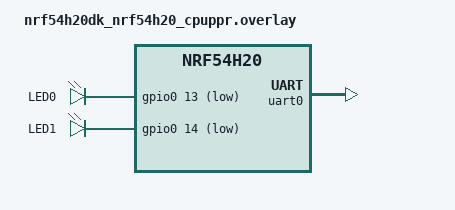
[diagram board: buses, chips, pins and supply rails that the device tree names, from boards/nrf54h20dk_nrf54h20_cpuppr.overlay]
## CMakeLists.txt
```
#
# Copyright (c) 2020 Nordic Semiconductor ASA
#
# SPDX-License-Identifier: LicenseRef-Nordic-5-Clause
#
cmake_minimum_required(VERSION 3.20.0)

find_package(Zephyr REQUIRED HINTS $ENV{ZEPHYR_BASE})

project(LED_strip_thread_network)

# NORDIC SDK APP START
target_sources(app PRIVATE src/main.c src/g_udp.c src/g_udp.h src/g_node.h)
# NORDIC SDK APP END

target_sources_ifdef(CONFIG_CLI_SAMPLE_MULTIPROTOCOL app PRIVATE src/ble.c)
target_sources_ifdef(CONFIG_CLI_SAMPLE_LOW_POWER app PRIVATE src/low_power.c)

if(CONFIG_CLI_SAMPLE_MULTIPROTOCOL AND CONFIG_OPENTHREAD_BLE_TCAT)
  message(FATAL_ERROR "Multiprotocol support and TCAT functionality are not compatible." )
endif()
```

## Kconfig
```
#
# Copyright (c) 2020 Nordic Semiconductor ASA
#
# SPDX-License-Identifier: LicenseRef-Nordic-5-Clause
#

menu "Zephyr Kernel"
source "Kconfig.zephyr"
endmenu

module = OT_COMMAND_LINE_INTERFACE
module-str = ot_cli
source "$(ZEPHYR_BASE)/subsys/logging/Kconfig.template.log_config"

config CLI_SAMPLE_LOW_POWER
	bool "Low power mode for the CLI sample"

config CLI_SAMPLE_MULTIPROTOCOL
	bool "Multiprotocol for the CLI sample"

config NRFX_GPIOTE0
	default y if SOC_SERIES_NRF51X || \
		     SOC_SERIES_NRF52X || \
		     (SOC_SERIES_NRF53X && !TRUSTED_EXECUTION_NONSECURE) || \
		     (SOC_SERIES_NRF91X && !TRUSTED_EXECUTION_NONSECURE)

config NRFX_GPIOTE1
	default y if (SOC_SERIES_NRF53X && TRUSTED_EXECUTION_NONSECURE) || \
		     (SOC_SERIES_NRF91X && TRUSTED_EXECUTION_NONSECURE)
```

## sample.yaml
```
sample:
  name: OpenThread CLI sample
  description: Test OpenThread Command Line Interface.

tests:
  sample.openthread.cli:
    sysbuild: true
    build_only: true
    tags:
      - ci_build
      - sysbuild
      - ci_samples_openthread
      - board
    platform_allow:
      - nrf52840dk/nrf52840
      - nrf52840dongle/nrf52840
    integration_platforms:
      - nrf52840dk/nrf52840
      - nrf52840dongle/nrf52840
  sample.openthread.cli.multiprotocol:
    sysbuild: true
    build_only: true
    tags:
      - ci_build
      - sysbuild
      - ci_samples_openthread
    platform_allow:
      - nrf52840dk/nrf52840
      - nrf52840dongle/nrf52840
    extra_args:
      - cli_SNIPPET="ci;logging;multiprotocol;tcp"
      - FILE_SUFFIX=ble
    integration_platforms:
      - nrf52840dk/nrf52840
      - nrf52840dongle/nrf52840
  sample.openthread.cli.singleprotocol:
    sysbuild: true
    build_only: true
    tags:
      - ci_build
      - sysbuild
      - ci_samples_openthread
    platform_allow:
      - nrf52840dk/nrf52840
      - nrf21540dk/nrf52840
      - nrf5340dk/nrf5340/cpuapp
      - nrf54l15dk/nrf54l15/cpuapp
      - nrf54l15dk/nrf54l10/cpuapp
      - nrf54l15dk/nrf54l15/cpuapp/ns
    extra_args: >
      cli_SNIPPET="ci;logging;tcp"
    integration_platforms:
      - nrf52840dk/nrf52840
      - nrf21540dk/nrf52840
      - nrf5340dk/nrf5340/cpuapp
      - nrf54l15dk/nrf54l15/cpuapp
      - nrf54l15dk/nrf54l10/cpuapp
      - nrf54l15dk/nrf54l15/cpuapp/ns
  sample.openthread.cli.usb:
    sysbuild: true
    build_only: true
    tags:
      - ci_build
      - sysbuild
      - ci_samples_openthread
    platform_allow:
      - nrf52840dk/nrf52840
      - nrf21540dk/nrf52840
      - nrf5340dk/nrf5340/cpuapp
    extra_args:
      - cli_SNIPPET="ci;logging;multiprotocol;tcp;usb"
      - FILE_SUFFIX=ble
    integration_platforms:
      - nrf52840dk/nrf52840
      - nrf21540dk/nrf52840
      - nrf5340dk/nrf5340/cpuapp
  sample.openthread.cli.low_power:
    sysbuild: true
    build_only: true
    tags:
      - ci_build
      - sysbuild
      - ci_samples_openthread
    platform_allow:
      - nrf52840dk/nrf52840
      - nrf5340dk/nrf5340/cpuapp
      - nrf54l15dk/nrf54l15/cpuapp
      - nrf54lm20dk/nrf54lm20a/cpuapp
    extra_args: >
      cli_SNIPPET="ci;low_power"
    integration_platforms:
      - nrf52840dk/nrf52840
      - nrf5340dk/nrf5340/cpuapp
      - nrf54l15dk/nrf54l15/cpuapp
      - nrf54lm20dk/nrf54lm20a/cpuapp
  # Build integration regression protection.
  sample.nrf_security.openthread.integration:
    sysbuild: true
    build_only: true
    tags:
      - sysbuild
      - ci_samples_openthread
    platform_allow: >
      nrf52840dk/nrf52840
    extra_args:
      - cli_SNIPPET=ci
      - CONFIG_NRF_SECURITY=y
    integration_platforms:
      - nrf52840dk/nrf52840
  sample.openthread.cli.tcat:
    sysbuild: true
    build_only: true
    tags:
      - ci_build
      - sysbuild
      - ci_samples_openthread
    platform_allow:
      - nrf52840dk/nrf52840
      - nrf21540dk/nrf52840
      - nrf5340dk/nrf5340/cpuapp
      - nrf54l15dk/nrf54l15/cpuapp
      - nrf54l15dk/nrf54l10/cpuapp
      - nrf54l15dk/nrf54l15/cpuapp/ns
    extra_args:
      - cli_SNIPPET="ci;tcat;tcp"
      - FILE_SUFFIX=ble
    integration_platforms:
      - nrf52840dk/nrf52840
      - nrf21540dk/nrf52840
      - nrf5340dk/nrf5340/cpuapp
      - nrf54l15dk/nrf54l15/cpuapp
      - nrf54l15dk/nrf54l10/cpuapp
      - nrf54l15dk/nrf54l15/cpuapp/ns
  sample.openthread.cli.diag_gpio:
    sysbuild: true
    build_only: true
    tags:
      - ci_build
      - sysbuild
      - ci_samples_openthread
    platform_allow:
      - nrf52840dk/nrf52840
      - nrf5340dk/nrf5340/cpuapp
      - nrf54l15dk/nrf54l15/cpuapp
      - nrf54l15dk/nrf54l10/cpuapp
      - nrf54l15dk/nrf54l15/cpuapp/ns
    extra_args: >
      cli_SNIPPET=diag_gpio
    integration_platforms:
      - nrf52840dk/nrf52840
      - nrf5340dk/nrf5340/cpuapp
      - nrf54l15dk/nrf54l15/cpuapp
      - nrf54l15dk/nrf54l10/cpuapp
      - nrf54l15dk/nrf54l15/cpuapp/ns
  sample.openthread.cli.l2:
    sysbuild: true
    build_only: true
    tags:
      - ci_build
      - sysbuild
      - ci_samples_openthread
    platform_allow:
      - nrf52840dk/nrf52840
      - nrf5340dk/nrf5340/cpuapp
      - nrf54l15dk/nrf54l15/cpuapp
      - nrf54l15dk/nrf54l10/cpuapp
      - nrf54lm20dk/nrf54lm20a/cpuapp
      - nrf54l15dk/nrf54l15/cpuapp/ns
    extra_args:
      - cli_SNIPPET="ci;l2;ci_l2"
    integration_platforms:
      - nrf52840dk/nrf52840
      - nrf5340dk/nrf5340/cpuapp
      - nrf54l15dk/nrf54l15/cpuapp
      - nrf54l15dk/nrf54l10/cpuapp
      - nrf54lm20dk/nrf54lm20a/cpuapp
      - nrf54l15dk/nrf54l15/cpuapp/ns
  sample.openthread.cli.multiprotocol.l2:
    sysbuild: true
    build_only: true
    tags:
      - ci_build
      - sysbuild
      - ci_samples_openthread
    platform_allow:
      - nrf52840dk/nrf52840
      - nrf5340dk/nrf5340/cpuapp
      - nrf54l15dk/nrf54l15/cpuapp
      - nrf54l15dk/nrf54l10/cpuapp
      - nrf54lm20dk/nrf54lm20a/cpuapp
      - nrf54l15dk/nrf54l15/cpuapp/ns
    extra_args:
      - cli_SNIPPET="ci;logging;multiprotocol;tcp;l2;ci_l2;logging_l2"
      - FILE_SUFFIX=ble
    integration_platforms:
      - nrf52840dk/nrf52840
      - nrf5340dk/nrf5340/cpuapp
      - nrf54l15dk/nrf54l15/cpuapp
      - nrf54l15dk/nrf54l10/cpuapp
      - nrf54lm20dk/nrf54lm20a/cpuapp
      - nrf54l15dk/nrf54l15/cpuapp/ns
```

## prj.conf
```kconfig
#
# Copyright (c) 2020 Nordic Semiconductor
#
# SPDX-License-Identifier: LicenseRef-Nordic-5-Clause
#

# Enable OpenThread
CONFIG_NETWORKING=y
CONFIG_OPENTHREAD=y
CONFIG_NET_L2_OPENTHREAD=y

# PANID in decimal format (0x0A8F)
CONFIG_OPENTHREAD_PANID=2703 
CONFIG_OPENTHREAD_XPANID="0A:8F:11:11:22:22:22:22"
CONFIG_OPENTHREAD_NETWORKKEY="0A:8F:22:33:44:55:66:77:88:99:aa:bb:cc:dd:0A:8F"
CONFIG_OPENTHREAD_CHANNEL=21
CONFIG_OPENTHREAD_NETWORK_NAME="Gabriel"
CONFIG_OPENTHREAD_FTD=y

CONFIG_NET_UDP=y
CONFIG_NET_IPV6=y
CONFIG_NET_IPV6_NBR_CACHE=y

# Network shell
CONFIG_SHELL=y
CONFIG_OPENTHREAD_SHELL=y
CONFIG_SHELL_ARGC_MAX=26
CONFIG_SHELL_CMD_BUFF_SIZE=416

# Increase Settings storage size
CONFIG_PM_PARTITION_SIZE_SETTINGS_STORAGE=0x8000

# Enable OpenThread features set
CONFIG_OPENTHREAD_NORDIC_LIBRARY_MASTER=y

CONFIG_GPIO=y
CONFIG_GPIO_SHELL=y
CONFIG_GPIO_NRFX=y
CONFIG_DK_LIBRARY=y
CONFIG_NRFX_GPPI=y



CONFIG_LOG=y
CONFIG_LOG_DEFAULT_LEVEL=3

CONFIG_LOG_BACKEND_UART=y
CONFIG_UART_CONSOLE=y
CONFIG_CONSOLE=y
```

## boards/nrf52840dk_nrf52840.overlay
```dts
/* SPDX-License-Identifier: Apache-2.0 */

/ {
	aliases {
		led0 = &led0;
		led1 = &led1;
		disp1 = &disp1;
	};

	leds {
		compatible = "gpio-leds";
		led0: led_0 {
			gpios = <&gpio0 13 GPIO_ACTIVE_LOW>;
			label = "LED0";
		};
	};

	disp1: disp_1 {
		gpios = <&gpio0 27 GPIO_ACTIVE_HIGH>;
		status = "okay";
	};
};

&gpio0 {
    status = "okay";
};

&uart0 {
	status = "okay";
	hw-flow-control;
};
```

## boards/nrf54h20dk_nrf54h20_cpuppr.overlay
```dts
/* SPDX-License-Identifier: Apache-2.0 */

/ {
	aliases {
		led0 = &led0;
		led1 = &led1;
	};

	leds {
		compatible = "gpio-leds";
		led0: led_0 {
			gpios = <&gpio0 13 GPIO_ACTIVE_LOW>;
			label = "LED0";
		};

		led1: led_1 {
			gpios = <&gpio0 14 GPIO_ACTIVE_LOW>;
			label = "LED1";
		};
	};
};

&gpiote130 {
	status = "okay";
};

&gpio9 {
	status = "okay";
};

&uart0 {
	status = "okay";
	hw-flow-control;
};
```

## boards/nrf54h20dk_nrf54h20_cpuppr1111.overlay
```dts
/* SPDX-License-Identifier: Apache-2.0 */

/ {
	aliases {
		led0 = &led0;
		led1 = &led1;
		disp1 = &disp1;
	};

	leds {
		compatible = "gpio-leds";
		led0: led_0 {
			gpios = <&gpio0 13 GPIO_ACTIVE_LOW>;
			label = "LED0";
		};
	};

	disp1: disp_1 {
			gpios = <&gpio0 27 GPIO_ACTIVE_HIGH>;
			status = "okay";
	};
};

&gpiote130 {
	status = "okay";
};

&gpio0 {
    status = "okay";
};

&uart0 {
	status = "okay";
	hw-flow-control;
};
```

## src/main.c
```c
/*
 * Copyright (c) 2020 Nordic Semiconductor ASA
 *
 * SPDX-License-Identifier: LicenseRef-Nordic-5-Clause
 */

#include <zephyr/kernel.h>
#include <zephyr/net/openthread.h>
#include <zephyr/net/net_l2.h>
#include <zephyr/drivers/gpio.h>
#include <openthread/thread.h>
#include <zephyr/drivers/uart.h>
#include <zephyr/syscalls/device.h>
#include <nrfx_gpiote.h>
#include "g_udp.h"

#define G_SERVER 1

LOG_MODULE_REGISTER(main, CONFIG_OT_COMMAND_LINE_INTERFACE_LOG_LEVEL);

#define WELLCOME_TEXT \
	"\n\r"\
	"\n\r"\
	"OpenThread Command Line Interface is now running.\n\r" \
	"Use the 'ot' keyword to invoke OpenThread commands e.g. " \
	"'ot thread start.'\n\r" \
	"For the full commands list refer to the OpenThread CLI " \
	"documentation at:\n\r" \
	"https://github.com/openthread/openthread/blob/master/src/cli/README.md\n\r"

/* The devicetree node identifier for the "led0" alias. */
#define LED0_NODE DT_ALIAS(led0)
#define LED1_NODE DT_ALIAS(led1)

// LED 1
#define GPIO003_PIN NRF_GPIO_PIN_MAP(0, 3) // For PCA10056
#define GPIO004_PIN NRF_GPIO_PIN_MAP(0, 4) // For PCA10056
#define GPIO028_PIN NRF_GPIO_PIN_MAP(0, 27) // For PCA10056
#define GPIO110_PIN NRF_GPIO_PIN_MAP(1, 10) // For PCA10056
#define GPIO111_PIN NRF_GPIO_PIN_MAP(1, 11) // For PCA10056
#define GPIO112_PIN NRF_GPIO_PIN_MAP(1, 12) // For PCA10056
#define GPIO113_PIN NRF_GPIO_PIN_MAP(1, 13) // For PCA10056
#define GPIO114_PIN NRF_GPIO_PIN_MAP(1, 14) // For PCA10056

// LED 2 
#define GPIO101_PIN NRF_GPIO_PIN_MAP(1, 1) // For PCA10056
#define GPIO102_PIN NRF_GPIO_PIN_MAP(1, 2) // For PCA10056
#define GPIO103_PIN NRF_GPIO_PIN_MAP(1, 3) // For PCA10056
#define GPIO104_PIN NRF_GPIO_PIN_MAP(1, 4) // For PCA10056
#define GPIO105_PIN NRF_GPIO_PIN_MAP(1, 5)// For PCA10056
#define GPIO107_PIN NRF_GPIO_PIN_MAP(1, 7) // For PCA10056
#define GPIO108_PIN NRF_GPIO_PIN_MAP(1, 8) // For PCA10056
#define GPIO109_PIN NRF_GPIO_PIN_MAP(1, 9) // For PCA10056

#define MAX_GPIOS 8

static uint8_t hour = 23;
static uint8_t minute = 40;

const uint8_t MASK_0 = 1 << 7;
const uint8_t MASK_1 = 1 << 6;
const uint8_t MASK_2 = 1 << 5;
const uint8_t MASK_3 = 1 << 4;
const uint8_t MASK_4 = 1 << 3;
const uint8_t MASK_5 = 1 << 2;
const uint8_t MASK_6 = 1 << 1;
const uint8_t MASK_7 = 1 << 0;

static bool showHour = false;

typedef struct {
	uint8_t gpios[MAX_GPIOS];
    uint8_t numbers[10];
} sled_t ; 

static const struct gpio_dt_spec led = GPIO_DT_SPEC_GET(LED0_NODE, gpios);
static const struct gpio_dt_spec led1 = GPIO_DT_SPEC_GET(LED1_NODE, gpios);

void openthread_network_start()
{
	openthread_init();

	int net_res = openthread_run();

	ot = openthread_get_default_instance();

	if(net_res != OT_ERROR_NONE)
		LOG_ERR("Openthread starting error [%d]", net_res);
		return;
	
	LOG_INF("Openthread network %s started ", otThreadGetNetworkName(ot));
	return;
}

extern void blink_led(void *p0, void *p1, void *p2)
{
	gpio_pin_configure_dt(&led, GPIO_OUTPUT_INACTIVE);
	gpio_pin_configure_dt(&led1, GPIO_OUTPUT_INACTIVE);
	
	while(1)
	{
		int role = otThreadGetDeviceRole(ot);

		if(role == OT_DEVICE_ROLE_ROUTER)
		{
			gpio_pin_set_dt(&led, 1);
		}
		else if(role == OT_DEVICE_ROLE_CHILD)
		{
			gpio_pin_toggle_dt(&led);
		}
		else
		{
			gpio_pin_set_dt(&led, 0);
		}

		if(role == OT_DEVICE_ROLE_LEADER)
		{
			gpio_pin_toggle_dt(&led1);
		}

		k_sleep(K_MSEC(1000));
	}
}

/*extern void controlTime(void *p0, void *p1, void *p2)
{
	gpio_pin_configure_dt(&disp1_0_27, GPIO_OUTPUT_ACTIVE);
	
	while(1)
	{
		gpio_pin_toggle_dt(&disp1_0_27);
	}
}*/

void activate_gpios(uint8_t number, bool pointActive, sled_t* led)
{
    uint8_t gpios_pos = led->numbers[number];
	for(int index = 0 ; index < MAX_GPIOS ; index++)
		nrf_gpio_pin_clear(led->gpios[index]);
	
	if(pointActive)
		nrf_gpio_pin_set(led->gpios[4]);

    if (gpios_pos & MASK_0)
        nrf_gpio_pin_set(led->gpios[0]);
    if (gpios_pos & MASK_1)
        nrf_gpio_pin_set(led->gpios[1]);
    if (gpios_pos & MASK_2)
        nrf_gpio_pin_set(led->gpios[2]);
    if (gpios_pos & MASK_3)
        nrf_gpio_pin_set(led->gpios[3]);
    if (gpios_pos & MASK_4)
        nrf_gpio_pin_set(led->gpios[4]);
    if (gpios_pos & MASK_5)
        nrf_gpio_pin_set(led->gpios[5]);
    if (gpios_pos & MASK_6)
        nrf_gpio_pin_set(led->gpios[6]);
    if (gpios_pos & MASK_7)
        nrf_gpio_pin_set(led->gpios[7]);
}


// Find the first digit
int firstDigit(int n)
{
    // Remove last digit from number
    // till only one digit is left
    while (n >= 10) 
        n /= 10;
    
    // return the first digit
    return n;
}

// Find the last digit
int lastDigit(int n)
{
    // return the last digit
    return (n % 10);
}

void updateTime(void)
{
    while(true)
    {        
        if (minute == 59)
        {
            minute = 0;
            if (hour == 23)
                hour = 0;
            else
                hour++;
        }
        else
            minute++;
		
		k_sleep(K_MSEC(60000));  
    }
}

K_THREAD_DEFINE(blink_led_tid, 1024, blink_led, NULL, NULL, NULL, K_LOWEST_APPLICATION_THREAD_PRIO, 0,0);
K_THREAD_DEFINE(update_ime_tid, 1024, updateTime, NULL, NULL, NULL, K_LOWEST_APPLICATION_THREAD_PRIO, 0,0);
//K_THREAD_DEFINE(controlTime_tid, 1024, controlTime, NULL, NULL, NULL, K_LOWEST_APPLICATION_THREAD_PRIO, 0,0);

int main(void)
{
	LOG_INF(WELLCOME_TEXT);

	LOG_INF("%d", GPIO028_PIN);
	LOG_INF("%d", GPIO101_PIN);
	LOG_INF("%d", GPIO110_PIN);
	LOG_INF("%d", GPIO111_PIN);


    sled_t sLed1 = {
        // GPIO003_PIN, GPIO004_PIN, GPIO028_PIN, GPIO110_PIN, GPIO111_PIN, GPIO112_PIN, GPIO113_PIN, GPIO114_PIN
		.gpios = {GPIO003_PIN, GPIO004_PIN, GPIO028_PIN, GPIO110_PIN, GPIO111_PIN, GPIO112_PIN, GPIO113_PIN, GPIO114_PIN},
        .numbers = {
           231, // 0
           36, // 1
           115, // 2
           118, // 3
           180, // 4
           214, // 5
           215, // 6
           100, // 7
           247, // 8
           244 // 9
        }
    };

	sled_t sLed2 = {
        // GPIO101_PIN, GPIO102_PIN, GPIO103_PIN, GPIO104_PIN, GPIO105_PIN, GPIO107_PIN, GPIO108_PIN, GPIO109_PIN
        .gpios = {GPIO103_PIN, GPIO102_PIN, GPIO101_PIN, GPIO104_PIN, GPIO105_PIN, GPIO107_PIN, GPIO108_PIN, GPIO109_PIN},
        .numbers = {
           231, // 0
           36, // 1
           115, // 2
           118, // 3
           180, // 4
           214, // 5
           215, // 6
           100, // 7
           247, // 8
           244 // 9
        }
    };

	openthread_network_start();

	if (!gpio_is_ready_dt(&led) || !gpio_is_ready_dt(&led1) ) {
		printf("GPIO not ready");
		return 0;
	}
	
//	k_thread_start(blink_led);
//	k_thread_start(controlTime);
	k_thread_start(updateTime);

	// LED 1
	for (uint8_t index = 0; index < MAX_GPIOS; index++)
	{
		nrf_gpio_cfg_output(sLed1.gpios[index]);
		nrf_gpio_cfg_output(sLed2.gpios[index]);
	}

	while (1)
	{

		showHour = !showHour;
		uint8_t digit1, digit2 = 0U;

		if(showHour)
		{
			digit1 = (uint8_t) firstDigit(hour);
			digit2 = (uint8_t) lastDigit(hour);
		}
		else
		{
			digit1 = (uint8_t) firstDigit(minute);
			digit2 = (uint8_t) lastDigit(minute);
		}

		activate_gpios(digit1, showHour, &sLed1);
		activate_gpios(digit2, showHour, &sLed2);

		k_sleep(K_MSEC(5000));
		//nrf_gpio_pin_set(sLed2.gpios[number]);                                                                                                                                       
    }
                                      

#if G_SERVER
	otError error = g_udp_start_server();
	if (error != OT_ERROR_NONE) {
        LOG_ERR("g_udp_start_server error: %d", error);
        return;
    }
#endif

	return 0;
}
```

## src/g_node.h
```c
#ifndef G_NODE
#define G_NODE

#include <openthread/thread.h>
#include <zephyr/net/openthread.h>

typedef struct g_node
{  
    uint8_t id;
    otIp6Address address;

} g_node_t;

#endif
```

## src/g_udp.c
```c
#include "g_udp.h"
#include "g_node.h"
#include <openthread/thread.h>
#include <zephyr/net/openthread.h>

LOG_MODULE_REGISTER(g_udp, CONFIG_OT_COMMAND_LINE_INTERFACE_LOG_LEVEL);

typedef struct node {
    g_node_t value;
    struct node *next;
    uint8_t size;
} node_t;

node_t* nodes = NULL;

node_t* addNode(node_t *head, g_node_t node)
{
    node_t *n = malloc(sizeof *n);
    if (!n) return head;
    n->value = node;
    n->next = head;
    return n;
}

void freeNodes(node_t *head) {
    while (head) {
        node_t *next = head->next;
        free(head);
        head = next;
    }
}

void printAddress(const otIp6Address*const addr)
{
	LOG_INF("%02x%02x:%02x%02x:%02x%02x:%02x%02x:%02x%02x:%02x%02x:%02x%02x:%02x%02x", 
            addr->mFields.m8[0],
            addr->mFields.m8[1],
            addr->mFields.m8[2],
            addr->mFields.m8[3],
            addr->mFields.m8[4],
            addr->mFields.m8[5],
            addr->mFields.m8[6],
            addr->mFields.m8[7],
            addr->mFields.m8[8],
            addr->mFields.m8[9],
            addr->mFields.m8[10],
            addr->mFields.m8[11],
            addr->mFields.m8[12],
            addr->mFields.m8[13],
            addr->mFields.m8[14],
            addr->mFields.m8[15]);
}

/* Callback when a message is received in the socket */
void g_control_handler(void *context,
                           otMessage *message,
                           const otMessageInfo *message_info)
{
    uint16_t length = otMessageGetLength(message);
    char buffer[length];
    memset(buffer, 0, sizeof(buffer));
    otMessageRead(message, 0, &buffer, length);
    
    if(buffer[0] == 0)
    {   
        uint8_t nodeId = atoi(buffer[1]);
        otIp6Address addr = message_info->mPeerAddr;
        g_node_t node = {1, addr};
        nodes = addNode(nodes, node);
    }


    return;
}

/* Callback when a message is received in the socket */
void g_node_handler(void *context,
                           otMessage *message,
                           const otMessageInfo *message_info)
{
    otIp6Address addr = message_info->mPeerAddr;
    printAddress(&message_info->mPeerAddr);
    g_node_t node = {1, addr};
    nodes = addNode(nodes, node);

    printAddress(&nodes->value.address);
    uint16_t length = otMessageGetLength(message);
    char buffer[length+1];
    memset(buffer, 0, sizeof(buffer));
    otMessageRead(message, 0, &buffer, length);
    buffer[length+1] = '\0'; 

    LOG_INF("Message type: %c", buffer[0]);

    if(buffer[0] == '0')
    {   
        int nodeId = atoi(&buffer[1]);
        otIp6Address addr = message_info->mPeerAddr;
        g_node_t node = {nodeId, addr};
        nodes = addNode(nodes, node);
        LOG_INF("NodeID: %d", nodeId);
    }

	return;
}

otError g_udp_start_server()
{
    otError error;
    otSockAddr addr = {0};

    addr.mPort = APP_PORT;

    ot = openthread_get_default_instance();

    error = otUdpOpen(ot, &socket, g_node_handler, ot);
    error = otUdpBind(ot, &socket, &addr, OT_NETIF_THREAD);
    return error;
}
```

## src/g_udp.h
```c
#ifndef g_UDP
#define g_UDP
#include <openthread/udp.h>
#include <zephyr/logging/log.h>

#define APP_PORT 9090

static struct otInstance *ot;
static otUdpSocket socket;

static void g_node_handler(void *context,
                           otMessage *message,
                           const otMessageInfo *message_info);
otError g_udp_start_server();
#endif
```
